# apollo510 register map
Vendor: Ambiq Micro; Series: Apollo; File version: 1.0
CPU: CM55 r1p1, little endian, MPU, FPU, double-precision FPU, DSP, I-cache, D-cache, VTOR, ITCM, DTCM, 4 interrupt priority bits, 0 interrupts, 8 SAU regions
Registers are 32-bit, read-write, reset 0x0 unless marked. A register's access mark holds for its fields unless they carry their own. Offsets are from the block's base; [hi:lo] are bit positions; lines under a group give offsets from that group; {n}, {i} and the like mark numbered series; 'fields as' and 'values as' point back to an identical list.

## PWRCTRL — PWR Controller Register Bank
Base 0x40021000
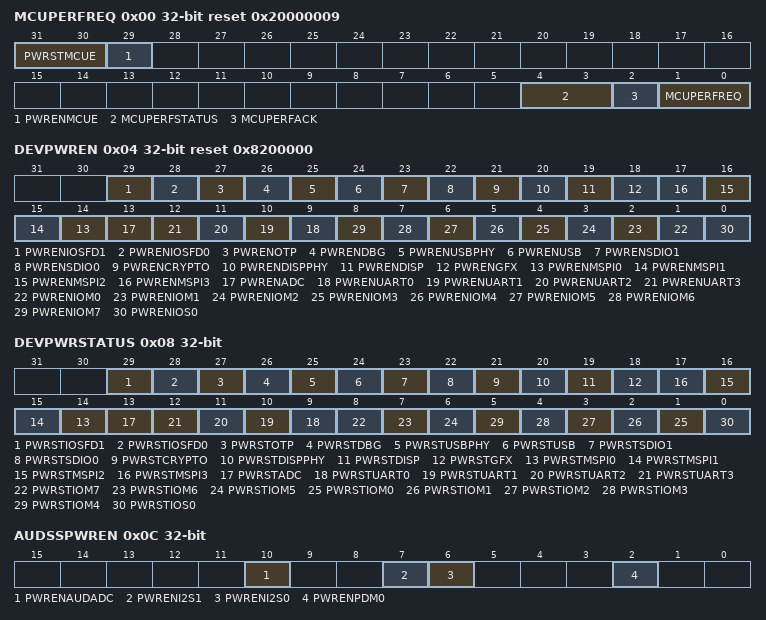
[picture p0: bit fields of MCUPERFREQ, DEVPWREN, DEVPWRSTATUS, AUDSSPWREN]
0x00 MCUPERFREQ reset 0x20000009 — This register provides the performance mode knobs for MCU. S/w should write the *PERFREQ field to desired mode and wait for the *PERFACK and check for the *PERFSTATUS. Some times system may not allow certain modes but *PERFACK should always follow *PERFREQ change.
  [31:30] PWRSTMCUE — Power Status MCUE subsystem
    3=RETENTION (Domain is in retention); 1=ON (Domain powered on); 0=OFF (Domain powered off)
  [29] PWRENMCUE — Powerup MCUE power domain
    1=EN (Enable); 0=DIS (Disable)
  [4:3] MCUPERFSTATUS — MCU Performance mode request
    1=LP (MCU is in LP mode (freq=96MHz)); 2=HP (MCU is in HP mode (freq=192MHz))
  [2] MCUPERFACK — Indicates the MCU performance status indicated in STATUS register is valid.
  [1:0] MCUPERFREQ — MCU Performance mode request
    1=LP (MCU to be run in LP mode (freq=96MHz)); 2=HP (MCU to be run in HP mode (freq=192MHz))
0x04 DEVPWREN reset 0x8200000 — This enables various peripherals power domains.
  [29] PWRENIOSFD1 — Power up IO FD Slave 1
    1=EN (Power up IO FD slave 1); 0=DIS (Power down IO FD slave 1)
  [28] PWRENIOSFD0 — Power up IO FD Slave 0
    1=EN (Power up IO FD slave 0); 0=DIS (Power down IO FD slave 0)
  [27] PWRENOTP — Powerup OTP power domain
    1=EN (Enable); 0=DIS (Disable)
  [26] PWRENDBG — Powerup DBG power domain
    1=EN (Enable); 0=DIS (Disable)
  [25] PWRENUSBPHY — Power up USB PHY
    1=EN (Power up USB PHY); 0=DIS (Power down USB PHY)
  [24] PWRENUSB — Power up USB controller
    1=EN (Power up USB); 0=DIS (Power down USB)
  [23] PWRENSDIO1 — Power up SDIO1 controller
    1=EN (Power up SDIO1); 0=DIS (Power down SDIO1)
  [22] PWRENSDIO0 — Power up SDIO0 controller
    1=EN (Power up SDIO0); 0=DIS (Power down SDIO0)
  [21] PWRENCRYPTO — Power up CRYPTO module
    1=EN (Power up CRYPTO); 0=DIS (Power down CRYPTO)
  [20] PWRENDISPPHY — Power up DISP PHY
    1=EN (Power up DISP PHY); 0=DIS (Power down DISP PHY)
  [19] PWRENDISP — Power up DISP controller
    1=EN (Power up DISP); 0=DIS (Power down DISP)
  [18] PWRENGFX — Power up GFX controller
    1=EN (Power up GFX); 0=DIS (Power down GFX)
  [n+14] PWRENMSPI{n} (n=0..3) — Power up MSPI Controller{n}
    1=EN (Power up MSPI{n}); 0=DIS (Power down MSPI{n})
  [13] PWRENADC — Power up ADC Digital Controller
    1=EN (Power up ADC); 0=DIS (Power Down ADC)
  [n+9] PWRENUART{n} (n=0..3) — Power up UART Controller {n}
    1=EN (Power up UART {n}); 0=DIS (Power down UART {n})
  [n+1] PWRENIOM{n} (n=0..7) — Power up IO Master {n}
    1=EN (Power up IO Master {n}); 0=DIS (Power down IO Master {n})
  [0] PWRENIOS0 — Power up IO Slave 0
    1=EN (Power up IO slave 0); 0=DIS (Power down IO slave 0)
0x08 DEVPWRSTATUS — This provides the power status for the peripheral device domains controlled through DEVPWREN register. Value of 1 means the device is powred up and ready to be used and 0 means its not powered up.
  [all] fields
    1=ON (Domain powered on); 0=OFF (Domain powered off)
  [29] PWRSTIOSFD1 — Power status IO FD Slave 1
  [28] PWRSTIOSFD0 — Power status IO FD Slave 0
  [27] PWRSTOTP — Power Status OTP
  [26] PWRSTDBG — Power Status DBG subsystem
  [25] PWRSTUSBPHY — Power Status USB PHY
  [24] PWRSTUSB — Power Status USB controller
  [23] PWRSTSDIO1 — Power Status SDIO1 controller
  [22] PWRSTSDIO0 — Power Status SDIO0 controller
  [21] PWRSTCRYPTO — Power Status CRYPTO module
  [20] PWRSTDISPPHY — Power Status DISP PHY
  [19] PWRSTDISP — Power Status DISP controller
  [18] PWRSTGFX — Power Status GFX controller
  [n+14] PWRSTMSPI{n} (n=0..3) — Power Status MSPI Controller{n}
  [13] PWRSTADC — Power Status ADC Digital Controller
  [n+9] PWRSTUART{n} (n=0..3) — Power Status UART Controller {n}
  [8] PWRSTIOM7 — Power Status IO Master 7
  [7] PWRSTIOM6 — Power Status IO Master 6
  [6] PWRSTIOM5 — Power Status IO Master 5
  [n+1] PWRSTIOM{n} (n=0..4) — Power status IO Master {n}
  [0] PWRSTIOS0 — Power status IO Slave 0
0x0C AUDSSPWREN — This enables various power domains in audio subsystem.
  [10] PWRENAUDADC — Power up audio subsystem ADC domain
    1=EN (Power up AUDADC); 0=DIS (Power down AUDADC)
  [7] PWRENI2S1 — Power up audio subsystem I2S1 domain
    1=EN (Power up I2S1); 0=DIS (Power down I2S1)
  [6] PWRENI2S0 — Power up audio subsystem I2S0 domain
    1=EN (Power up I2S0); 0=DIS (Power down I2S0)
  [2] PWRENPDM0 — Power up audio subsystem PDM0 domain
    1=EN (Power up PDM0); 0=DIS (Power down PDM0)
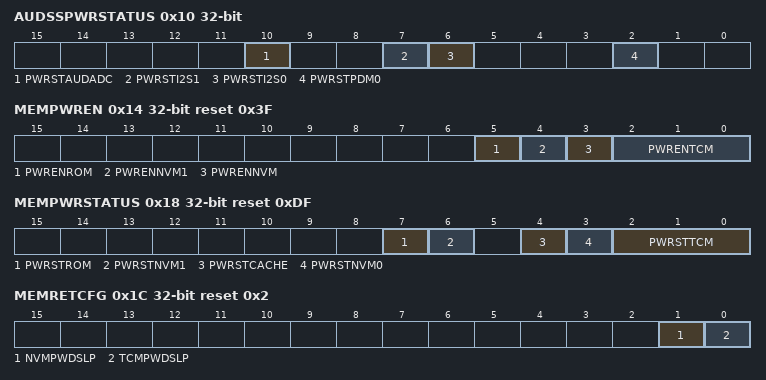
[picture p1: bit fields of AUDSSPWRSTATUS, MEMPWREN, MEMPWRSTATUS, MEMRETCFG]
0x10 AUDSSPWRSTATUS — This provides the power status for the peripheral domains controlled through AUDSSPWREN register. Value of 1 means the device is powred up and ready to be used and 0 means its not powered up.
  [all] fields
    1=ON (Domain powered on); 0=OFF (Domain powered off)
  [10] PWRSTAUDADC — Power Status audio subsystem ADC domain
  [7] PWRSTI2S1 — Power Status audio subsystem I2S1 domain
  [6] PWRSTI2S0 — Power Status audio subsystem I2S0 domain
  [2] PWRSTPDM0 — Power Status audio subsystem PDM0 domain
0x14 MEMPWREN reset 0x3F — Enables individual banks of memories. When a PWREN field is set, power is enabled to the memory or specific bank of memory. This register works in conjunction with the MEMRETCFG register. If a field in this register is not set, then power is always disabled to the memory bank. In the case of NVM, to enable NVM1, NVM0 must also be enabled. Disabling power to NVM0 also disables power to NVM1.
  [5] PWRENROM — Power up ROM.
    1=EN (Power up ROM); 0=DIS (Power down ROM)
  [4] PWRENNVM1 — Power up NVM1. PWRENNVM (Bit 3) MUST ALSO BE SET to 0x1.
    1=EN (Power up NVM1. NVM1 can only be enabled if NVM0 is Enabled); 0=DIS (Power down only NVM1. Independently power down NVM1.)
  [3] PWRENNVM — Power up NVM
    1=EN (Power up NVM0. This bit must be set to power up NVM1.); 0=DIS (Power down NVM0 and NVM1.)
  [2:0] PWRENTCM — Power up Combination of DTCM and ITCM. Only 3 Combinations are allowed - 0x1, 0x3 and 0x7. And, Setting 0x2 selects ITCM128K_DTCM256K, Setting 0x4, 0x5, 0x6 selects ITCM256K_DTCM512K.
    0=NONE (Do not enable power to any TCMs); 1=ITCM32K_DTCM128K (Power ON only 32k of ITCM and 128k of DTCM); 3=ITCM128K_DTCM256K (Power ON only 128k of ITCM and 256k of DTCM); 7=ITCM256K_DTCM512K (Power ON 256k of ITCM and 512k of DTCM)
0x18 MEMPWRSTATUS reset 0xDF — It provides the power status for all the memory banks including- caches, nvm (0 and 1) and all the SRAM groups. The status here should reflect the enable provided by the MEMPWREN register. There may be a lag time between setting the bits in MEMPWREN register and MEMPWRSTATUS register, due to the need to cycle the power gate and isolation seqeunces to the memory banks.
  [7] PWRSTROM — This bit is 1 if power is supplied to ROM
  [6] PWRSTNVM1 — This bit is 1 if power is supplied to NVM 1
  [4] PWRSTCACHE — This bit is 1 if power is supplied to Cache
  [3] PWRSTNVM0 — This bit is 1 if power is supplied to NVM 0
  [2:0] PWRSTTCM — Power status for xTCM. Each bit corresponds to one of the TCMs. bit0=TCM0_0, bit1=TCM0_1, bit2=TCM1.
    0=NONE (Do not enable power to any DTCMs); 1=ITCM32K_DTCM128K (Only lower 32k of ITCM and 128k of DTCM is powered up); 3=ITCM128K_DTCM256K (Only lower 128k of ITCM and 256k of DTCM is powered up); 7=ITCM256K_DTCM512K (All 256k of ITCM and 512k of DTCM is powered up)
0x1C MEMRETCFG reset 0x2 — This register's fields control the power down of the NVM and TCM in deep sleep.
  [1] NVMPWDSLP — Powers down NVM in deep sleep when set.
    0=DIS (NVM is kept powered on during deep sleep); 1=EN (NVM is powered down during deep sleep)
  [0] TCMPWDSLP — Powers down all enabled ITCM and DTCM in deep sleep when set (memory is not retained). Enabled ITCM and DTCM are as set in the PWRENTCM field of the MEMPWREN register and the SKUITCM and SUDTCM fields in the MCUCTRL_SKU register. If power-down is disabled (TCMPWDSLP is cleared), then upon wake the data within the TCMs is retained. Do not set this bit if the TCM bank is used as the target for DMA transfer while CPU in deep sleep.
    0=DIS (All enabled TCM is kept powered on and retained during deep sleep); 1=EN (All enabled TCM is powered down (not retained) during deep sleep)
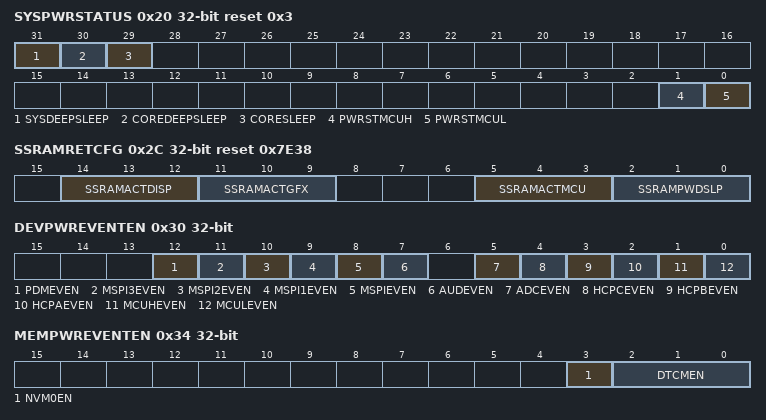
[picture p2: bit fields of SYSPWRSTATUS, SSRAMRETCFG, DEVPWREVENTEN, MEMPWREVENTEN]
0x20 SYSPWRSTATUS reset 0x3 — Power ON Status for domains that are not part of devpwrstatus or mempwrstatus
  [31] SYSDEEPSLEEP — Indicates all device domains powered down and MCU entered DEEPSLEEP state since it was last cleared. Write 1 to to clear it.
  [30] COREDEEPSLEEP — Indicates MCU entered DEEPSLEEP state since it was last cleared. Write 1 to to clear it.
  [29] CORESLEEP — Indicates MCU entered SLEEP state since it was last cleared. Write 1 to to clear it.
  [1] PWRSTMCUH — Power Domain status for MCUH
  [0] PWRSTMCUL — Power Domain status for MCUL
0x24 SSRAMPWREN — This register enables the individual banks for the memories. When set, power will be enabled to the banks. This register works in conjunction with the SSRAMRETCFG register. If this register is not set, then power will always be disabled to the memory bank.
  [2:0] PWRENSSRAM — Power up SRAM groups
    0=NONE (Do not power ON any of the SRAM banks); 1=GROUP0 (Power ON only SRAM0 group (lower 1M)); 2=GROUP1 (Power ON only SRAM1 group (middle 1M)); 4=GROUP2 (Power ON only SRAM2 group (upper 1M)); 7=ALL (All shared SRAM banks (SSRAM0 1M + SSRAM1 1M + SSRAM2 1M) powered ON)
0x28 SSRAMPWRST reset 0x7 — It provides the power status for shared sram banks. The status here should reflect the enable provided by the SSRAMPWREN register.
  [2:0] SSRAMPWRST — Each bit corresponds to one 1M SSRAM group. Power Status- 1:ON, 0:OFF See SSRAMPWREN PWRENSSRAM for bit mapping. For example, a value of 2 in this field would mean that SSRAM1 is powered up and SSRAM0 is powered down.
0x2C SSRAMRETCFG reset 0x7E38 — This controls the power down of the Shared SRAM banks in deep sleep mode. If this is set, then the power for that SRAM bank will be gated when the core goes into deep sleep. Upon wake, the data within the SRAMs will be erased. If this is not set, retention voltage will be applied to the SRAM bank when none of the CPU agents are in powered up and active mode. Do not set this if the SRAM bank is used as the target for DMA transfer while CPU in deepsleep.
  [14:12] SSRAMACTDISP — Keep the memory domain active based on DISP state. Each bit corresponds to a domain. 1: Keep SRAM active 0: Powerup on demand (i.e. when DISP is powered up)
  [11:9] SSRAMACTGFX — Keep the memory domain active based on GFX state. Each bit corresponds to a domain. 1: Keep SRAM active 0: Powerup on demand (i.e. when GFX is powered up)
  [5:3] SSRAMACTMCU — Keep the memory domain active based on MCU state. Each bit corresponds to a domain. 1: Keep SRAM active 0: Wakeup on demand (i.e. when MCU is powered up)
  [2:0] SSRAMPWDSLP — Selects which shared SRAM banks are powered down in deep sleep mode, causing the contents of the bank to be lost.
    0=NONE (All banks retained); 1=GROUP0 (Power down only SRAM group0); 2=GROUP1 (Power down only SRAM group1); 4=GROUP2 (Power down only SRAM group2); 7=ALL (All shared SRAM banks powered down)
0x30 DEVPWREVENTEN — This register controls which feature trigger will result in an event to the CPU. It includes all the power on status for the core domains. If any bits are set, then if the domain is turned on, it will result in an event to the ARM core.
  [12] PDMEVEN — Control PDM power-on status event
    1=EN (Enable PDM power-on status event); 0=DIS (Disable PDM power-on status event)
  [11] MSPI3EVEN — Control MSPI3 power-on status event
    1=EN (Enable MSPI3 power-on status event); 0=DIS (Disable MSPI3 power-on status event)
  [10] MSPI2EVEN — Control MSPI2 power-on status event
    1=EN (Enable MSPI2 power-on status event); 0=DIS (Disable MSPI2 power-on status event)
  [9] MSPI1EVEN — Control MSPI1 power-on status event
    1=EN (Enable MSPI1 power-on status event); 0=DIS (Disable MSPI1 power-on status event)
  [8] MSPIEVEN — Control MSPI power-on status event
    1=EN (Enable MSPI power-on status event); 0=DIS (Disable MSPI power-on status event)
  [7] AUDEVEN — Control AUD power-on status event
    1=EN (Enable AUD power-on status event); 0=DIS (Disable AUD power-on status event)
  [5] ADCEVEN — Control ADC power-on status event
    1=EN (Enable ADC power-on status event); 0=DIS (Disable ADC power-on status event)
  [4] HCPCEVEN — Control HCPC power-on status event
    1=EN (Enable HCPC power-on status event); 0=DIS (Disable HCPC power-on status event)
  [3] HCPBEVEN — Control HCPB power-on status event
    1=EN (Enable HCPB power-on status event); 0=DIS (Disable HCPB power-on status event)
  [2] HCPAEVEN — Control HCPA power-on status event
    1=EN (Enable HCPA power-on status event); 0=DIS (Disable HCPA power-on status event)
  [1] MCUHEVEN — Control MCUH power-on status event
    1=EN (Enable MCHU power-on status event); 0=DIS (Disable MCUH power-on status event)
  [0] MCULEVEN — Control MCUL power-on status event
    1=EN (Enable MCUL power-on status event); 0=DIS (Disable MCUL power-on status event)
0x34 MEMPWREVENTEN — This register controls which power enable for the memories will result in an event to the CPU. It includes all the power on status for the memory domains. If any bits are set, then if the domain is turned on, it will result in an event to the ARM core.
  [3] NVM0EN — Control NVM power-on status event
    1=EN (Enable NVM status event); 0=DIS (Disables NVM status event)
  [2:0] DTCMEN — Enable DTCM power-on status event
    0=NONE (Do not enable DTCM power-on status event); 1=GROUP0DTCM0EN (Enable GROUP0_DTCM0 power on status event); 2=GROUP0DTCM1EN (Enable GROUP0_DTCM1 power on status event); 3=GROUP0EN (Enable DTCMs in group0 power on status event); 4=GROUP1EN (Enable DTCMs in group1 power on status event); 7=ALL (Enable all DTCM power on status event)
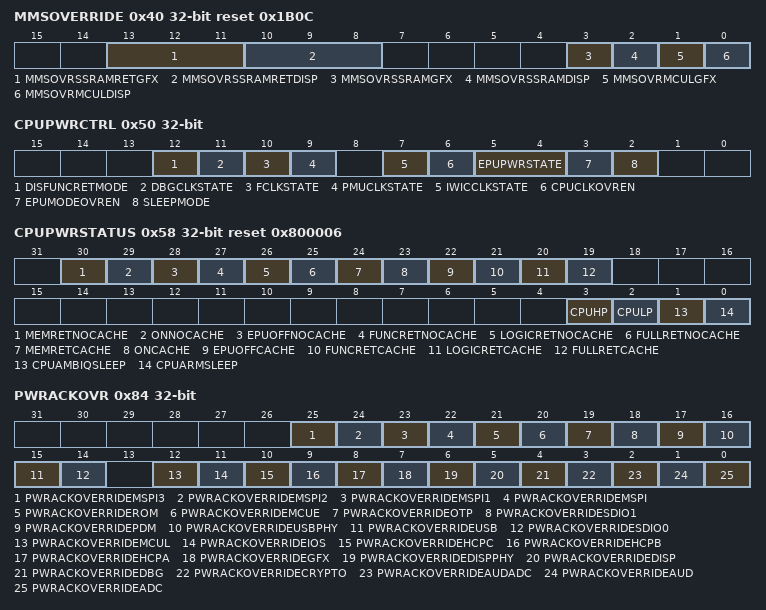
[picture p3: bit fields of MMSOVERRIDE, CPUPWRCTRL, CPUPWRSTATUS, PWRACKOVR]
0x40 MMSOVERRIDE reset 0x1B0C — Power domain behavior overrides related to MMS ( Multimedia System ).
  [13:11] MMSOVRSSRAMRETGFX — If set, retention equation doesn't consider GFX. Each bit corresponds to a domain.
    1=ALWAYSON (When PD_GFX is off, retention is always okay for PD_GFX domain.); 0=PGSTATE (When PD_GFX is off, retention is okay based on the state of PD_GFX domain and SSRAMRETCFG.)
  [10:8] MMSOVRSSRAMRETDISP — If set, retention equation doesn't consider DISP. Each bit corresponds to a domain.
    1=ALWAYSON (When PD_DISP is off, retention is always okay for PD_DISP domain.); 0=PGSTATE (When PD_DISP is off, retention is okay based on the state of PD_DISP domain and SSRAMRETCFG.)
  [3] MMSOVRSSRAMGFX — MMS override for SSRAM power state by PD_GFX power setting.
    1=NOGFX (SSRAM power state is not affected by PD_GFX setting.); 0=PD_GFX (SSRAM power state set by SSRAMPWREN_PWRENSSRAM is overridden by PD_GFX setting.)
  [2] MMSOVRSSRAMDISP — MMS override for SSRAM power state by PD_DISP power setting.
    1=NODISP (SSRAM power state is not affected by PD_DISP setting.); 0=PD_DISP (SSRAM power state set by SSRAMPWREN_PWRENSSRAM is overridden by PD_DISP setting.)
  [1] MMSOVRMCULGFX — MMS override for MCUL on by PD_GFX setting. NOTE: THIS BIT MUST ALWAYS BE SET TO 0.
    0=MCULON (When PD_GFX is on, MCUL is forced on.); 1=MCULOFF (PD_GFX Does not affect the state of PD_MCUL)
  [0] MMSOVRMCULDISP — MMS override for MCUL on by PD_DISP setting.
    0=MCULON (When PD_DISP is on, MCUL is on.); 1=MCULOFF (When PD_DISP is on, MCUL is still off.)
0x50 CPUPWRCTRL — This register contains override settings to override legacy_mode trim bit setting
  [12] DISFUNCRETMODE — SW Override to disable FUNC_RET mode
    0=NORMAL_OPERATION (FUNC_RET mode is enabled); 1=DIS_FUNC_RET (FUNC_RET mode is disabled)
  [11] DBGCLKSTATE — DBG Clock state
    0=NORMAL_OPERATION (Clock follows normal HW sequencing); 1=CLOCK_ON (Clock stays enabled)
  [10] FCLKSTATE — FCLK Clock state
    values as DBGCLKSTATE
  [9] PMUCLKSTATE — PMU Clock state
    values as DBGCLKSTATE
  [7] IWICCLKSTATE — IWIC Clock state
    values as DBGCLKSTATE
  [6] CPUCLKOVREN — CPU clock override enable
    0=OVERRIDE_OFF (CPU Clocks follow normal HW sequencing); 1=OVERRIDE_ON (Clock state will be overriden by above bits)
  [5:4] EPUPWRSTATE — EPU Power State
    1=EPU_RET (EPU in retention); 2=EPU_ON (EPU is ON)
  [3] EPUMODEOVREN — EPU Mode override
    0=EPU_NORM (EPU follows normal CPU transitions as per legacy or P channel mode); 1=EPU_OVERRIDE (Override EPU state to match EPUPWRSTATE)
  [2] SLEEPMODE — Control to select between Ambiq sleep and ARM sleep
    0=AMBIQ_SLEEP (PMU gates off CLKIN.); 1=ARM_SLEEP (PMU does not gate off CLKIN, uses M55 internal clock gating)
0x54 PWRCTRLMODESTATUS — This register indicates power control operational mode
  [0] LEGACYMODEST — Legacy Mode value
    1=LEGACY_MODE_ON (Power control works in legacy mode (As per sleeping and sleepdeep signals from M55 Core)); 0=LEGACY_MODE_OFF (Power control works according to P/Q channel interface signals coming from PMU)
0x58 CPUPWRSTATUS reset 0x800006 — This register indicates the accepted power state request sent to pwr_ctrl
  [30] MEMRETNOCACHE — Indicates M55 entered the MEM_RET (NO Cache) power state, Write 1 to clear
  [29] ONNOCACHE — Indicates M55 entered the ON (NO Cache) power state, Write 1 to clear
  [28] EPUOFFNOCACHE — Indicates M55 entered the EPU_OFF (NO Cache) power state, Write 1 to clear
  [27] FUNCRETNOCACHE — Indicates M55 entered the FUNC_RET (NO Cache) power state, Write 1 to clear
  [26] LOGICRETNOCACHE — Indicates M55 entered the LOGIC_RET (NO Cache) power state, Write 1 to clear
  [25] FULLRETNOCACHE — Indicates M55 entered the FULL_RET (NO Cache) power state, Write 1 to clear
  [24] MEMRETCACHE — Indicates M55 entered the MEM_RET (Cache) power state, Write 1 to clear
  [23] ONCACHE — Indicates M55 entered the ON (Cache) power state, Write 1 to clear
  [22] EPUOFFCACHE — Indicates M55 entered the EPU_OFF (Cache) power state, Write 1 to clear
  [21] FUNCRETCACHE — Indicates M55 entered the FUNC_RET (Cache) power state, Write 1 to clear
  [20] LOGICRETCACHE — Indicates M55 entered the LOGIC_RET (Cache) power state, Write 1 to clear
  [19] FULLRETCACHE — Indicates M55 entered the FULL_RET (Cache) power state, Write 1 to clear
  [3] CPUHP — Indicates M55 entered HP mode. Write 1 to clear
  [2] CPULP — Indicates M55 entered LP mode. Write 1 to clear
  [1] CPUAMBIQSLEEP — Indicates M55 entered Ambiq SLEEP mode (clkin gated). Write 1 to clear
  [0] CPUARMSLEEP — Indicates M55 entered ARM SLEEP mode (clkin ungated, internal M55 clock gating via Q-channel signaling). Write 1 to clear
0x84 PWRACKOVR — This register contains override bit fields for various power domain power switch acknowledge notification. As a part of power up sequnce, Power controller will look for power switch ack to advance power up sequence. It is possible for power controller to be a forever wait state in case of a unforeseen HW bug. This register defines a bit fileds to work around if needed in such a situation. The default behavior is to use HW power switch ack. Software can set it to override this feature for each power switch.
  [all] fields
    0=DEFAULT (Hardware generates Power switch ack); 1=SWOVRRIDE (Software override or defeaure mode. Will bypass HW generated power ack)
  [25] PWRACKOVERRIDEMSPI3 — Power switch acknowledgement override from Power switch to power control ST MC
  [24] PWRACKOVERRIDEMSPI2 — Power switch acknowledgement override from Power switch to power control ST MC
  [23] PWRACKOVERRIDEMSPI1 — Power switch acknowledgement override from Power switch to power control ST MC
  [22] PWRACKOVERRIDEMSPI — Power switch acknowledgement override from Power switch to power control ST MC
  [21] PWRACKOVERRIDEROM — Power switch acknowledgement override from Power switch to power control ST MC
  [20] PWRACKOVERRIDEMCUE — Power switch acknowledgement override from Power switch to power control ST MC
  [19] PWRACKOVERRIDEOTP — Power switch acknowledgement override from Power switch to power control ST MC
  [18] PWRACKOVERRIDESDIO1 — Power switch acknowledgement override from Power switch to power control ST MC
  [17] PWRACKOVERRIDEPDM — Power switch acknowledgement override from Power switch to power control ST MC
  [16] PWRACKOVERRIDEUSBPHY — Power switch acknowledgement override from Power switch to power control ST MC
  [15] PWRACKOVERRIDEUSB — Power switch acknowledgement override from Power switch to power control ST MC
  [14] PWRACKOVERRIDESDIO0 — Power switch acknowledgement override from Power switch to power control ST MC
  [12] PWRACKOVERRIDEMCUL — Power switch acknowledgement override from Power switch to power control ST MC
  [11] PWRACKOVERRIDEIOS — Power switch acknowledgement override from Power switch to power control ST MC
  [10] PWRACKOVERRIDEHCPC — Power switch acknowledgement override from Power switch to power control ST MC
  [9] PWRACKOVERRIDEHCPB — Power switch acknowledgement override from Power switch to power control ST MC
  [8] PWRACKOVERRIDEHCPA — Power switch acknowledgement override from Power switch to power control ST MC
  [7] PWRACKOVERRIDEGFX — Power switch acknowledgement override from Power switch to power control ST MC
  [6] PWRACKOVERRIDEDISPPHY — Power switch acknowledgement override from Power switch to power control ST MC
  [5] PWRACKOVERRIDEDISP — Power switch acknowledgement override from Power switch to power control ST MC
  [4] PWRACKOVERRIDEDBG — Power switch acknowledgement override from Power switch to power control ST MC
  [3] PWRACKOVERRIDECRYPTO — Power switch acknowledgement override from Power switch to power control ST MC
  [2] PWRACKOVERRIDEAUDADC — Power switch acknowledgement override from Power switch to power control ST MC
  [1] PWRACKOVERRIDEAUD — Power switch acknowledgement override from Power switch to power control ST MC
  [0] PWRACKOVERRIDEADC — Power switch acknowledgement override from Power switch to power control ST MC
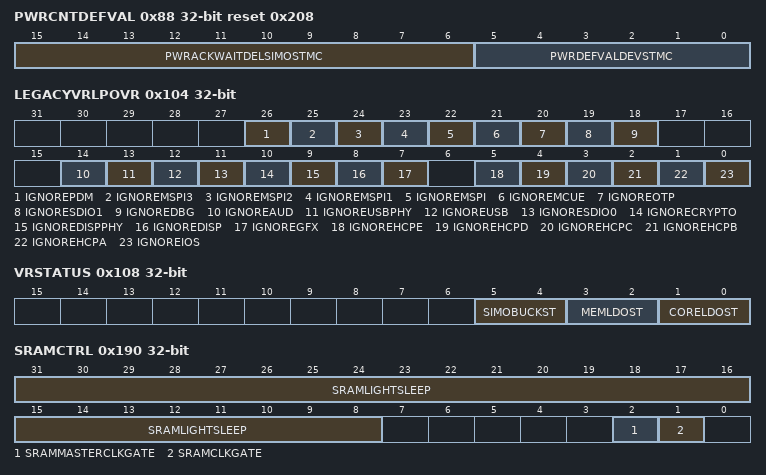
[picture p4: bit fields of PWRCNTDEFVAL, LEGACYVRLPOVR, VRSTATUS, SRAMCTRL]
0x88 PWRCNTDEFVAL reset 0x208 — This register contains programmble dealy values for various state michines. Fields contain dev st machine default value, SIMOBUCK state machine wait delay counter etc.
  [15:6] PWRACKWAITDELSIMOSTMC — Default counter max for buck ST MC
  [5:0] PWRDEFVALDEVSTMC — Default count max value for dev ST MC
0x8C GFXPERFREQ — This register provides the performance mode knobs for GFX.
  [1:0] GFXPERFREQ — GFX Performance mode request
    0=HFRC_96MHz (GFX to be run in LP mode (freq=96MHz)); 1=HFRC_192MHz (GFX to be run in HP1 mode (freq=192MHz)); 2=HFRC2_125MHz (GFX to be run in HP2 mode (freq=125MHz)); 3=HFRC2_250MHz (GFX to be run in HP3 mode (freq=250MHz))
0x90 GFXPWRSWSEL — This register provides the performance mode knobs for GFX.
  [0] GFXVDDSEL — GFX VDD select
    0=VDDC (GFX VDD select VDDC); 1=VDDF (GFX VDD select VDDF)
0x94 EPURETCFG reset 0x1 — This controls the retention of EPU in system deep sleep mode. If this is set, when core goes into deepsleep mode, EPU flops will be in logic retention. When this is not set, EPU will be powered down when core goes into deepsleep.
  [0] EPURETSLP — EPU retention select
    1=EN (EPU will be in retention when core is in deepsleep); 0=DIS (EPU will be powered down when core is in deepsleep)
0x100 VRCTRL — This register includes additional debug control bits. This is an internal Ambiq-only register. Customers should not attempt to change this or else functionality cannot be guaranteed.
  [0] SIMOBUCKEN — Enables and Selects the SIMO Buck as the supply for the low-voltage power domains. It takes the initial value from the bit set in Customer INFO space.
    1=EN (Enable the SIMO Buck); 0=DIS (Disable the SIMO Buck)
0x104 LEGACYVRLPOVR — When an override is set for a power domain, VR logic will ignore that power domain state in making a decision to go into lp state.
  [26] IGNOREPDM
  [25] IGNOREMSPI3 — Ignore MSPI
  [24] IGNOREMSPI2 — Ignore MSPI
  [23] IGNOREMSPI1 — Ignore MSPI
  [22] IGNOREMSPI
  [21] IGNOREMCUE
  [20] IGNOREOTP
  [19] IGNORESDIO1
  [18] IGNOREDBG
  [14] IGNOREAUD
  [13] IGNOREUSBPHY
  [12] IGNOREUSB — Ignore USB Control
  [11] IGNORESDIO0
  [10] IGNORECRYPTO
  [9] IGNOREDISPPHY
  [8] IGNOREDISP — Ignore DISP Control
  [7] IGNOREGFX
  [5] IGNOREHCPE
  [4] IGNOREHCPD
  [3] IGNOREHCPC
  [2] IGNOREHCPB
  [1] IGNOREHCPA
  [0] IGNOREIOS
0x108 VRSTATUS — Provides BUCK and LDOs status.
  [5:4] SIMOBUCKST — Indicates SIMO BUCK status. bit[1] indicates ON/OFF and bit[0] indicates ACT/LP
    0=OFF (Indicates the the SIMO BUCK is OFF.); 2=LP (Indicates the the SIMO BUCK is ON and in LP mode.); 3=ACT (Indicates the the SIMO BUCK is ON and in ACT mode.)
  [3:2] MEMLDOST — Indicates MEMLDO status. bit[1] indicates ON/OFF and bit[0] indicates ACT/LP.
    0=OFF (Indicates the the MEMLDO is OFF.); 2=LP (Indicates the the MEMLDO is ON and in LP mode.); 3=ACT (Indicates the the MEMLDO is ON and in ACT mode.)
  [1:0] CORELDOST — Indicates CORELDO status. bit[1] indicates ON/OFF and bit[0] indicates ACT/LP.
    0=OFF (Indicates the the CORELDO is OFF.); 2=LP (Indicates the the CORELDO is ON and in LP mode.); 3=ACT (Indicates the the CORELDO is ON and in ACT mode.)
0x190 SRAMCTRL — This register provides additional fine-tune power management controls for the SRAMs and the SRAM controller. This includes enabling light sleep for the SRAM and TCM banks, and clock gating for reduced dynamic power.
  [31:8] SRAMLIGHTSLEEP — Light Sleep enable for each TCM/SRAM bank. When 1, corresponding bank will be put into light sleep. For optimal power, banks should be put into light sleep while the system is active but the bank has minimal or no accesses.
    0xFFF=ALL (Enable LIGHT SLEEP for ALL SRAMs); 0=DIS (Disables LIGHT SLEEP for ALL SRAMs)
  [2] SRAMMASTERCLKGATE — This bit is 1 when the master clock gate is enabled (top-level clock gate for entire SRAM block)
    1=EN (Enable Master SRAM Clock Gate); 0=DIS (Disables Master SRAM Clock Gating)
  [1] SRAMCLKGATE — This bit is 1 if clock gating is allowed for individual system SRAMs
    1=EN (Enable Individual SRAM Clock Gating); 0=DIS (Disables Individual SRAM Clock Gating)
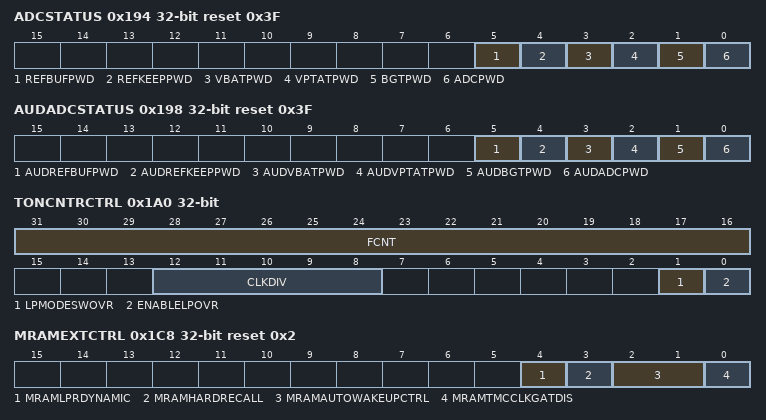
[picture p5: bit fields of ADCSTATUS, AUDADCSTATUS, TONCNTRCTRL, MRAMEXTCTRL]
0x194 ADCSTATUS reset 0x3F — This provides the power status for various blocks within the ADC. These status comes directly from the ADC module and is captured through this interface.
  [5] REFBUFPWD — This bit indicates that the ADC REFBUF is powered down
  [4] REFKEEPPWD — This bit indicates that the ADC REFKEEP is powered down
  [3] VBATPWD — This bit indicates that the ADC VBAT resistor divider is powered down
  [2] VPTATPWD — This bit indicates that the ADC temperature sensor input buffer is powered down
  [1] BGTPWD — This bit indicates that the ADC Band Gap is powered down
  [0] ADCPWD — This bit indicates that the ADC is powered down
0x198 AUDADCSTATUS reset 0x3F — This provides the power status for various blocks within the audio ADC. These status comes directly from the audio ADC module and is captured through this interface.
  [5] AUDREFBUFPWD — This bit indicates that the ADC REFBUF is powered down
  [4] AUDREFKEEPPWD — This bit indicates that the ADC REFKEEP is powered down
  [3] AUDVBATPWD — This bit indicates that the ADC VBAT resistor divider is powered down
  [2] AUDVPTATPWD — This bit indicates that the ADC temperature sensor input buffer is powered down
  [1] AUDBGTPWD — This bit indicates that the ADC Band Gap is powered down
  [0] AUDADCPWD — This bit indicates that the ADC is powered down
0x1A0 TONCNTRCTRL — Controls each of the ton counters
  [31:16] FCNT — frame width for ton counters
  [12:8] CLKDIV — frame width for ton counters
  [1] LPMODESWOVR — lp mode sw override
  [0] ENABLELPOVR — vdds lp mode override enable
0x1A4 LPOVRTHRESHVDDS — Low power override threshold for VDDS
  [31:0] LPOVRTHRESHVDDS — vdds lp override threshold for ton counter comparator
0x1A8 LPOVRHYSTCNT — Low power override hysteresis count
  [31:0] LPOVRHYSTCNT — lp hysteresis count
0x1AC LPOVRTHRESHVDDF — Low power override for VDDF
  [31:0] LPOVRTHRESHVDDF — vddf lp override threshold for ton counter comparator
0x1B4 LPOVRTHRESHVDDC — Low power override for VDDC
  [31:0] LPOVRTHRESHVDDC — vddc lp override threshold for ton counter comparator
0x1BC LPOVRTHRESHVDDCLV — Low power override for VDDC_LV
  [31:0] LPOVRTHRESHVDDCLV — vddc_lv lp override threshold for ton counter comparator
0x1C4 LPOVRSTAT — Low power override status register
  [0] LPOVRTRIG — VDDS LP override has been triggered; write 1 to clear
0x1C8 MRAMEXTCTRL reset 0x2 — MRAM control register
  [4] MRAMLPRDYNAMIC — bypass lpr dynamic mode
  [3] MRAMHARDRECALL — over write send recall command from hardware side
  [2:1] MRAMAUTOWAKEUPCTRL — over write rst_auto_wk for TMC IP. auto wake up is enabled at default. write 0x3 to this field to disable the auto wake up.
  [0] MRAMTMCCLKGATDIS — disable last tmc_clk/tmc_clk_inv clock gate
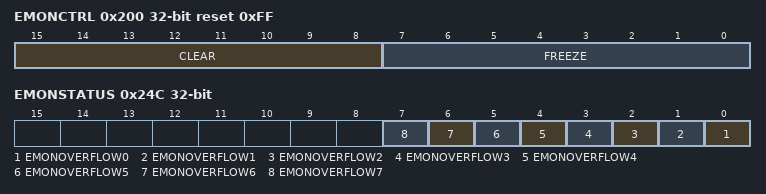
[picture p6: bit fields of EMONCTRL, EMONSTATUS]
0x200 EMONCTRL reset 0xFF — Controls each of the energy monitor conuters
  [15:8] CLEAR — Clear the counter. Each bit corresponds to a counter. 0: Let the counter run run on its input clk. 1: Clear the counter
  [7:0] FREEZE — Freeze the counter. Each bit corresponds to a counter. 0: Let the counter run. 1: Stop the counter.
{0x204+4i} EMONCFG{i} (i=0..7) — The counter increments when the counter is enabled and the mode selected here matches the power mode.
  [7:0] EMONSEL{i} — Power modes for incrementing the counter
    0=NEVER (Never increment the counter); 1=ALWAYS (Always increment the counter); 2=MCUSLEEP (Increment the counter for MCU sleep mode); 3=MCUDEEPSLEEP (Increment the counter for MCU deepsleep mode)
{0x228+4i} EMONCOUNT{i} (i=0..7) — Energy Monitor count value for counter {i}
  [31:0] EMONCOUNT{i} — Energy Monitor count value counter {i}
0x24C EMONSTATUS — Energy Monitor status
  [n] EMONOVERFLOW{n} (n=0..7) — Energy Monitor counter{n} overflow
